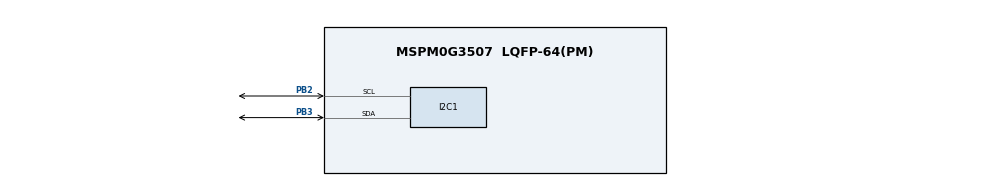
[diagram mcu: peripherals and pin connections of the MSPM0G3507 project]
//@cliArgs --device "MSPM0G350X" --package "LQFP-64(PM)" --part "Default"
//@v2CliArgs --device "MSPM0G3507" --package "LQFP-64(PM)"
// @cliArgs --board /ti/boards/LP_MSPM0G3507 --rtos nortos

/**
 * Import the modules used in this configuration.
 */
const I2C    = scripting.addModule("/ti/driverlib/I2C", {}, false);
const I2C1   = I2C.addInstance();
const SYSCTL = scripting.addModule("/ti/driverlib/SYSCTL");

/**
 * Write custom configuration values to the imported modules.
 */

const Board = scripting.addModule("/ti/driverlib/Board", {}, false);

I2C1.$name                         = "I2C_0";
I2C1.basicEnableController         = true;
I2C1.peripheral.$assign            = "I2C1";
I2C1.peripheral.sdaPin.$assign     = "PB3";
I2C1.peripheral.sclPin.$assign     = "PB2";
I2C1.sdaPinConfig.enableConfig     = true;
I2C1.sdaPinConfig.internalResistor = "PULL_UP";
I2C1.sclPinConfig.enableConfig     = true;
I2C1.sclPinConfig.internalResistor = "PULL_UP";

SYSCTL.forceDefaultClkConfig = true;
